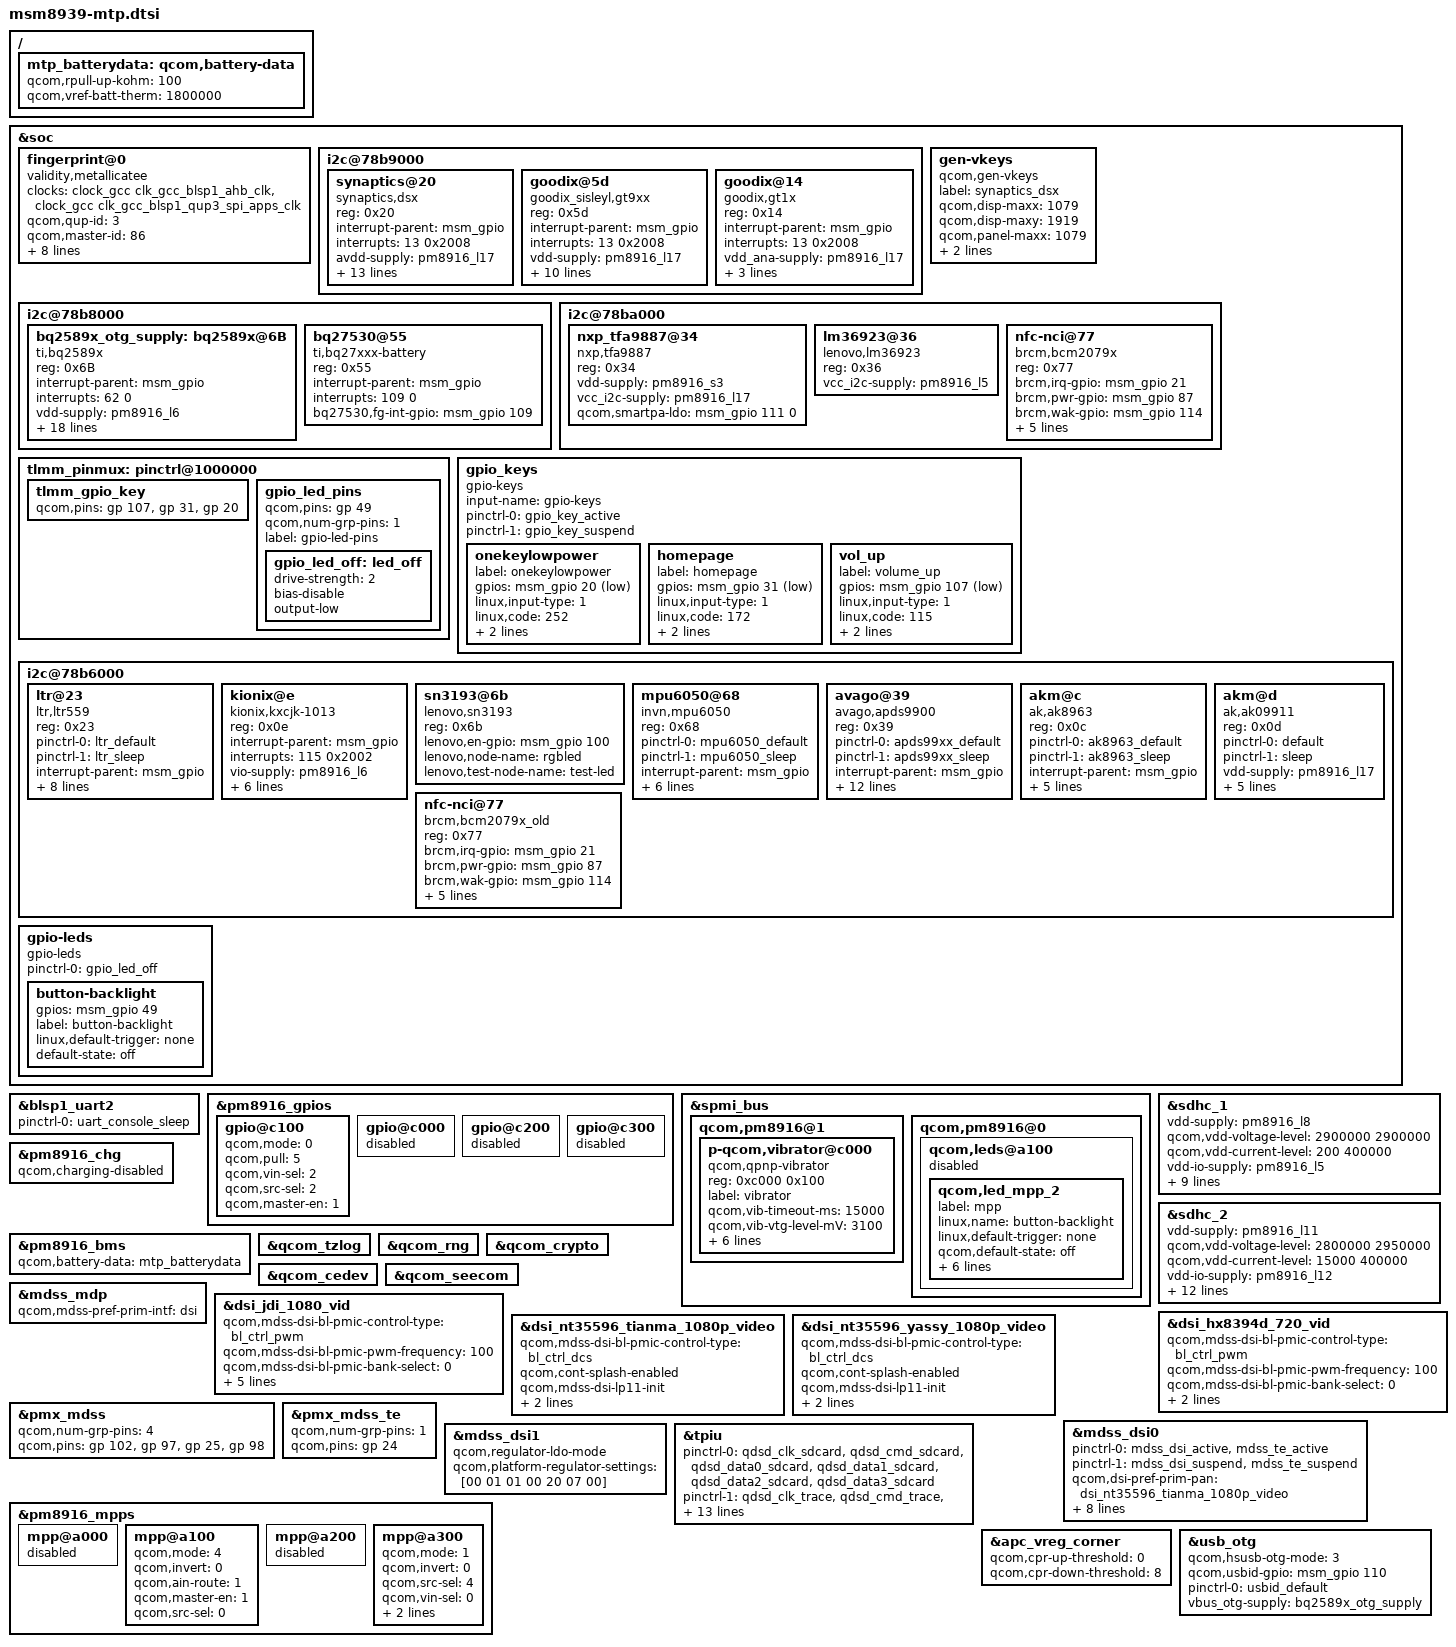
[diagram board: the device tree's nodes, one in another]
/* Copyright (c) 2014-2015, The Linux Foundation. All rights reserved.
 *
 * This program is free software; you can redistribute it and/or modify
 * it under the terms of the GNU General Public License version 2 and
 * only version 2 as published by the Free Software Foundation.
 *
 * This program is distributed in the hope that it will be useful,
 * but WITHOUT ANY WARRANTY; without even the implied warranty of
 * MERCHANTABILITY or FITNESS FOR A PARTICULAR PURPOSE.  See the
 * GNU General Public License for more details.
 */

#include "msm8939-pinctrl.dtsi"
#include "msm8939-camera-sensor-mtp.dtsi"

&soc {
    /* lenovo-sw, chenzz3, lock spi in trustzone, begin */
    fingerprint@0 {
        /* driver name */
        compatible = "validity,metallicatee";
        /* pinctrl for spi */
        /*qcom,use-pinctrl;
        pinctrl-names = "default", "sleep";
        pinctrl-0 = <&spi0_default &spi0_cs0_active>;
        pinctrl-1 = <&spi0_sleep &spi0_cs0_sleep>;*/
        /* clock for spi */
        clocks = <&clock_gcc clk_gcc_blsp1_ahb_clk>,
                 <&clock_gcc clk_gcc_blsp1_qup3_spi_apps_clk>;
        clock-names = "iface_clk", "core_clk";
        /* pass BLSP ID to TZ */
        qcom,qup-id = <3>;
        /* other setting */
        qcom,master-id = <86>;
        /*reg = <0>;
        spi-max-frequency = <11000000>;*/
        /* sensor configuration */
        interrupt-parent = <&msm_gpio>;
        interrupts = <121 0>;
        synaptics,gpio_drdy = <&msm_gpio 121 0x1>;
        synaptics,gpio_sleep = <&msm_gpio 120 0x0>;
        synaptics,gpio_3p3v = <&msm_gpio 82 0x1>;
        vdd-supply = <&pm8916_l16>;
        qcom,vdd-voltage-level = <1800000 1800000>;
        qcom,vdd-current-level = <200 400000>;
    };
    /* lenovo-sw, chenzz3, lock spi in trustzone, end */
	i2c@78b9000 { /* BLSP1 QUP5 */
		synaptics@20 {
			compatible = "synaptics,dsx";
			reg = <0x20>;
			interrupt-parent = <&msm_gpio>;
			interrupts = <13 0x2008>;
			avdd-supply = <&pm8916_l17>;
			vdd-supply = <&pm8916_l6>;
			/* pins used by touchscreen */
			pinctrl-names = "pmx_ts_active","pmx_ts_suspend","pmx_ts_suspend";
			pinctrl-0 = <&ts_int_active &ts_reset_active>;
			pinctrl-1 = <&ts_int_suspend &ts_reset_suspend>;
			pinctrl-2 = <&ts_release>;
			synaptics,irq-gpio = <&msm_gpio 13 0x2008>;
			synaptics,reset-gpio = <&msm_gpio 12 0x0>;
			synaptics,i2c-pull-up;
			synaptics,power-down;
			synaptics,disable-gpios;
			synaptics,display-coords = <0 0 1079 1919>;
			synaptics,panel-coords = <0 0 1079 2084>;
			/* Underlying clocks used by secure touch */
			clocks = <&clock_gcc clk_gcc_blsp1_ahb_clk>,
			 <&clock_gcc clk_gcc_blsp1_qup5_i2c_apps_clk>;
			clock-names = "iface_clk", "core_clk";
		};

        /* Begin, lenovo-sw wengjun1 add 2015-3-1, add for touchpanel config. */
		goodix@5d {
			compatible = "goodix_sisleyl,gt9xx";
			reg = <0x5d>;
			interrupt-parent = <&msm_gpio>;
			interrupts = <13 0x2008>;
			vdd-supply = <&pm8916_l17>;
			vcc_i2c-supply = <&pm8916_l6>;
			/* pins used by touchscreen */
			pinctrl-names = "pmx_ts_active","pmx_ts_suspend";
			pinctrl-0 = <&ts_int_active &ts_reset_active>;
			pinctrl-1 = <&ts_int_suspend &ts_reset_suspend>;
			goodix,reset-gpio = <&msm_gpio 12 0x0>;
			goodix,irq-gpio = <&msm_gpio 13 0x2008>;
			goodix,ctp-gpio = <&msm_gpio 74 0x0>;
			//goodix,ldo-en-gpio = <&msmgpio 15 0x00>;
			goodix,panel-coords = <0 0 1080 1920>;
			goodix,display-coords = <0 0 1080 1920>;
			goodix,button-map= <158 102 139>;
			goodix,family-id = <0x0>;
		};
        /* End, lenovo-sw wengjun1 add 2015-3-1, add for touchpanel config. */

        /* Begin, lenovo-sw wengjun1 add 2015-3-1, add for touchpanel config. */

		goodix@14 {
			compatible = "goodix,gt1x";
			reg = <0x14>;
			interrupt-parent = <&msm_gpio>;
			interrupts = <13 0x2008>;
			vdd_ana-supply = <&pm8916_l17>;
			vcc_i2c-supply = <&pm8916_l6>;
			goodix,rst-gpio = <&msm_gpio 12 0x00>;
			goodix,irq-gpio = <&msm_gpio 13 0x00>;
            };
        /* End, lenovo-sw wengjun1 add 2015-3-1, add for touchpanel config. */
	};

	gen-vkeys {
		compatible = "qcom,gen-vkeys";
		label = "synaptics_dsx";
		qcom,disp-maxx = <1079>;
		qcom,disp-maxy = <1919>;
		qcom,panel-maxx = <1079>;
		qcom,panel-maxy = <2084>;
		qcom,key-codes = <158 139 172 217>;
	};
	
	i2c@78b8000 { /* BLSP1 QUP4 */
	bq2589x_otg_supply: bq2589x@6B {
			compatible = "ti,bq2589x";
			reg = <0x6B>;
			interrupt-parent = <&msm_gpio>;
			interrupts = <62 0>;
			vdd-supply = <&pm8916_l6>;
			/* pins used by touchscreen 
			pinctrl-names = "pmx_ts_active","pmx_ts_suspend";
			pinctrl-0 = <&ts_int_active &ts_reset_active>;
			pinctrl-1 = <&ts_int_suspend &ts_reset_suspend>;*/
			charger,en-gpio = <&msm_gpio 52 0x0>;
			charger,irq-gpio = <&msm_gpio 62 0>;
			charger,ok-gpio = <&msm_gpio 100 0>;
			charger,fast-charger-en-gpio = <&msm_gpio 3 0>;
			//charger,otg-en-gpio = <&msm_gpio 72 0>;
			charger,otg-short-gpio = <&msm_gpio 75 0>;
			charger,max-temp = <500>;
			charger,min-temp = <0>;
			charger,warm-temp = <460>;
			charger,cool-temp = <150>;
			charger,ichg-max = <500>;
			charger,ibat-max = <2000>;
			charger,ibat-warm = <2000>;
			charger,ibat-cool = <480>;
			charger,vbat-warm = <4112>;
			charger,vbat-cool = <4352>;
			charger,vbat-mv = <4352>;
			charger,iterm-ma = <150>;
			regulator-name = "bq2589x_otg_vreg";
		};
		bq27530@55 {
			reg = <0x55>;
	        compatible = "ti,bq27xxx-battery";
			interrupt-parent = <&msm_gpio>;
			interrupts = <109 0>;
			bq27530,fg-int-gpio = <&msm_gpio 109 0>;
           };

	};

	i2c@78ba000 { /* BLSP1 QUP6 */
		//lenovo-sw lumy1 remove for bcm nfc
		/*nfc-nci@e {
			compatible = "qcom,nfc-nci";
			reg = <0x0e>;
			qcom,irq-gpio = <&msm_gpio 21 0x00>;
			qcom,dis-gpio = <&msm_gpio 20 0x00>;
			qcom,clk-src = "BBCLK2";
			interrupt-parent = <&msm_gpio>;
			interrupts = <21 0>;
			interrupt-names = "nfc_irq";
			pinctrl-names = "nfc_active","nfc_suspend";
			pinctrl-0 = <&nfc_int_active &nfc_disable_active>;
			pinctrl-1 = <&nfc_int_suspend &nfc_disable_suspend>;
			qcom,clk-gpio = <&pm8916_gpios 2 0>;
			clocks = <&clock_rpm clk_bb_clk2_pin>;
			clock-names = "ref_clk";
		};*/

	/* lenovo-sw zhangrc2 add for smartpa begin */
    nxp_tfa9887@34 {
		compatible = "nxp,tfa9887";
		reg = <0x34>;
		vdd-supply = <&pm8916_s3>;
		vcc_i2c-supply = <&pm8916_l17>;
        qcom,smartpa-ldo = <&msm_gpio 111 0>;
		};
    /* lenovo-sw zhangrc2 add for smartpa end */

	    /*lenovo.sw2 houdz1 add for lm36923 start*/
		lm36923@36 {
			compatible = "lenovo,lm36923";
			reg = <0x36>;
			vcc_i2c-supply = <&pm8916_l5>;
		};
	    /*lenovo.sw2 houdz1 add for lm36923 end*/
		/* lenovo-sw lumy1 add for brcm2079x nfc*/
		/*nq@2b {
			compatible = "qcom,nq-nci";
			reg = <0x2b>;
			qcom,nq-irq = <&msm_gpio 21 0x00>;
			qcom,nq-ven = <&msm_gpio 20 0x00>;
			qcom,nq-firm = <&msm_gpio 45 0x00>;
			qcom,nq-clkreq = <&pm8916_gpios 2 0>;
			qcom,clk-src = "BBCLK2";
			interrupt-parent = <&msm_gpio>;
			interrupts = <21 0>;
			interrupt-names = "nfc_irq";
			pinctrl-names = "nfc_active","nfc_suspend";
			pinctrl-0 = <&nfc_int_active &nfc_disable_active>;
			pinctrl-1 = <&nfc_int_suspend &nfc_disable_suspend>;
			clocks = <&clock_rpm clk_bb_clk2_pin>;
			clock-names = "ref_clk";
		};*/
		nfc-nci@77 {
		    compatible = "brcm,bcm2079x";
		    reg = <0x77>;
		    brcm,irq-gpio = <&msm_gpio 21 0x00>;
		    brcm,pwr-gpio = <&msm_gpio 87 0x00>;
		    brcm,wak-gpio = <&msm_gpio 114 0x00>;
		    interrupt-parent = <&msm_gpio>;
		    interrupts = <21 0>;
		    vcc_i2c-supply = <&pm8916_l5>;
		    qcom,clk-gpio = <&pm8916_gpios 2 0>;
		    clocks = <&clock_rpm clk_bb_clk2_pin>;
		    clock-names = "ref_clk";
		};
	};
/*add by lixh10 for one key power down && home key 2015-03-10 start*/
	tlmm_pinmux: pinctrl@1000000 {
			tlmm_gpio_key {
			qcom,pins = <&gp 107>, <&gp 31>, <&gp 20>;
			};
		};
	gpio_keys {
		compatible = "gpio-keys";
		input-name = "gpio-keys";
		pinctrl-names = "tlmm_gpio_key_active","tlmm_gpio_key_suspend";
		pinctrl-0 = <&gpio_key_active>;
		pinctrl-1 = <&gpio_key_suspend>;

		onekeylowpower {
			label = "onekeylowpower";
			gpios = <&msm_gpio 20 0x1>;
			linux,input-type = <1>;
			linux,code = <252>;
			gpio-key,wakeup;
			debounce-interval = <15>;
		};

		homepage {
			label = "homepage";
			gpios = <&msm_gpio 31 0x1>;
			linux,input-type = <1>;
			linux,code = <172>;
			gpio-key,wakeup;
			debounce-interval = <15>;
		};

		vol_up {
			label = "volume_up";
			gpios = <&msm_gpio 107 0x1>;
			linux,input-type = <1>;
			linux,code = <115>;
			gpio-key,wakeup;
			debounce-interval = <15>;
		};
	};
/*add by lixh10 for one key power down && home key 2015-03-10 end*/
	i2c@78b6000 { /* BLSP1 QUP2 */
		/*lenovo-sw caoyi1 add for P-sensor and L-sensor  begin*/
		ltr@23 { /*ALS and proximity sensor*/
			compatible = "ltr,ltr559";
			reg = <0x23>;
			pinctrl-names = "default","sleep";
			pinctrl-0 = <&ltr_default>;
			pinctrl-1 = <&ltr_sleep>;
			interrupt-parent = <&msm_gpio>;
			interrupts = <113 0x2002>;
			liteon,intr=<113>;
			ltr,irq-gpio = <&msm_gpio 113 0x2002>;
			vdd-supply = <&pm8916_l17>;
			vio-supply = <&pm8916_l6>;
			ltr,ps-threshold = <150>;
			ltr,ps-hysteresis-threshold = <80>;
			ltr,als-polling-time = <200>;
		};
		/*lenovo-sw caoyi1 add for P-sensor and L-sensor  end*/

		/*lenovo-sw caoyi1 modify for G-sensor 20150508 begin*/
		kionix@e {/*Accelerometer sensor*/
			compatible = "kionix,kxcjk-1013";
			reg = <0x0e>;
			interrupt-parent = <&msm_gpio>;
			interrupts = <115 0x2002>;
			/*vdd-supply = <&pm8916_l17>;*/
			vio-supply = <&pm8916_l6>;
			kionix,min_interval = <5>;
			kionix,poll_interval = <100>;
			kionix,accel_direction = <3>;
			kionix,accel_irq_use_drdy = <0>;
			kionix,accel_res = <12>;	
			kionix,accel_g_range = <2>;
		};
		/*lenovo-sw caoyi1 modify for G-sensor 20150508 end*/

		/*lenovo.sw2 houdz1 add(start)*/
		sn3193@6b {
			compatible = "lenovo,sn3193";
			reg = <0x6b>;
			lenovo,en-gpio = <&msm_gpio 100 0x00>;
			lenovo,node-name = "rgbled";
			lenovo,test-node-name = "test-led";
		};
		/*lenovo.sw2 houdz1 add(end)*/
		mpu6050@68 { /* Gyroscope and accelerometer sensor combo */
			compatible = "invn,mpu6050";
			reg = <0x68>;
			pinctrl-names = "mpu_default","mpu_sleep";
			pinctrl-0 = <&mpu6050_default>;
			pinctrl-1 = <&mpu6050_sleep>;
			interrupt-parent = <&msm_gpio>;
			interrupts = <115 0x2>;
			vdd-supply = <&pm8916_l17>;
			vlogic-supply = <&pm8916_l16>;
			vi2c-supply = <&pm8916_l6>;
			invn,gpio-int = <&msm_gpio 115 0x2>;
			invn,place = "Portrait Down Back Side";
		};

		avago@39 { /* Ambient light and proximity sensor */
			compatible = "avago,apds9900";
			reg = <0x39>;
			pinctrl-names = "default","sleep";
			pinctrl-0 = <&apds99xx_default>;
			pinctrl-1 = <&apds99xx_sleep>;
			interrupt-parent = <&msm_gpio>;
			interrupts = <113 0x2002>;
			vdd-supply = <&pm8916_l17>;
			vio-supply = <&pm8916_l6>;
			avago,irq-gpio = <&msm_gpio 113 0x2002>;
			avago,ps-threshold = <600>;
			avago,ps-hysteresis-threshold = <500>;
			avago,ps-pulse = <8>;
			avago,ps-pgain = <0>;
			avago,als-B = <186>;
			avago,als-C = <75>;
			avago,als-D = <129>;
			avago,ga-value = <560>;
		};

		akm@c {
			compatible = "ak,ak8963";
			reg = <0x0c>;
			pinctrl-names = "ak8963_default", "ak8963_sleep";
			pinctrl-0 = <&ak8963_default>;
			pinctrl-1 = <&ak8963_sleep>;
			interrupt-parent = <&msm_gpio>;
			interrupts = <69 0x2>;
			vdd-supply = <&pm8916_l17>;
			vio-supply = <&pm8916_l6>;
			ak,layout = <0x6>;
			ak,auto-report;
		};

		/*lenovo-sw caoyi1 add for M-sensor begin*/
		akm@d {
			compatible = "ak,ak09911";
			reg = <0x0d>;
			pinctrl-names = "default","sleep";
			pinctrl-0 = <&default>;
			pinctrl-1 = <&sleep>;
			vdd-supply = <&pm8916_l17>;
			vio-supply = <&pm8916_l6>;
			akm,layout = <0x0>;
			akm,gpio_rstn = <&msm_gpio 106 0x0>;
			akm,auto-report;
			akm,use-hrtimer;
		};
		/*lenovo-sw caoyi1 add for M-sensor end*/

		/* brcm2079x nfc configuration for old HW<DVT2-2 */
		nfc-nci@77 {
		    compatible = "brcm,bcm2079x_old";
		    reg = <0x77>;
		    brcm,irq-gpio = <&msm_gpio 21 0x00>;
		    brcm,pwr-gpio = <&msm_gpio 87 0x00>;
		    brcm,wak-gpio = <&msm_gpio 114 0x00>;
		    interrupt-parent = <&msm_gpio>;
		    interrupts = <21 0>;
		    vcc_i2c-supply = <&pm8916_l6>;
		    qcom,clk-gpio = <&pm8916_gpios 2 0>;
		    clocks = <&clock_rpm clk_bb_clk2_pin>;
		    clock-names = "ref_clk";
		};
	};

	gpio-leds {
		compatible = "gpio-leds";
		status = "okay";
		pinctrl-names = "default";
		pinctrl-0 = <&gpio_led_off>;

		button-backlight {
			gpios = <&msm_gpio 49 0>;
			label = "button-backlight";
			linux,default-trigger = "none";
			default-state = "off";
			//retain-state-suspended;
		};
	};
	tlmm_pinmux: pinctrl@1000000{
		gpio_led_pins {
			qcom,pins = <&gp 49>;
			qcom,num-grp-pins = <1>;
			label = "gpio-led-pins";
			gpio_led_off: led_off {
				drive-strength = <2>;
				bias-disable;
				output-low;
			};
		};

	};
	
};

&blsp1_uart2 {
	status = "ok";
	pinctrl-names = "default";
	pinctrl-0 = <&uart_console_sleep>;
};

&pm8916_gpios {
	gpio@c100 { /* GPIO 2 */
		/* NFC_CLK_REQ */
		qcom,mode = <0>; /* QPNP_PIN_MODE_DIG_IN */
		qcom,pull = <5>; /* QPNP_PIN_PULL_NO */
		qcom,vin-sel = <2>; /* QPNP_PIN_VIN2 */
		qcom,src-sel = <2>; /* QPNP_PIN_SEL_FUNC_1 */
		qcom,master-en = <1>;
	};
};
&spmi_bus {
	qcom,pm8916@1 {
		p-qcom,vibrator@c000 {
//*modify by lixh10 for pwm control 2015-0303 start*/
/*
			status = "okay";
			qcom,vib-timeout-ms = <15000>;
			qcom,vib-vtg-level-mV = <2700>;
*/
			status = "okay";
			compatible = "qcom,qpnp-vibrator";
			reg = <0xc000 0x100>;
			label = "vibrator";
			qcom,vib-timeout-ms = <15000>;
			qcom,vib-vtg-level-mV = <3100>;
			qcom,en-gpio = <&msm_gpio 56 0x00>;
			qcom,mode = "dtest1";
			qcom,pwm-channel = <0>;
			qcom,period-us = <50000>; //40
			qcom,duty-us = <40000>;	//30
			qcom,active-low;
//*modify by lixh10 for pwm control 2015-0303 end*/
		};
	};

	qcom,pm8916@0 {
		qcom,leds@a100 {
			status = "disabled";
			qcom,led_mpp_2 {
				label = "mpp";
				linux,name = "button-backlight";
				linux,default-trigger = "none";
				qcom,default-state = "off";
				qcom,max-current = <40>;
				qcom,current-setting = <5>;
				qcom,id = <6>;
				qcom,mode = "manual";
				qcom,source-sel = <1>;
				qcom,mode-ctrl = <0x60>;
			};
		};
	};
};

&sdhc_1 {
	vdd-supply = <&pm8916_l8>;
	qcom,vdd-voltage-level = <2900000 2900000>;
	qcom,vdd-current-level = <200 400000>;

	vdd-io-supply = <&pm8916_l5>;
	qcom,vdd-io-always-on;
	qcom,vdd-io-lpm-sup;
	qcom,vdd-io-voltage-level = <1800000 1800000>;
	qcom,vdd-io-current-level = <200 60000>;

	pinctrl-names = "active", "sleep";
	pinctrl-0 = <&sdc1_clk_on &sdc1_cmd_on &sdc1_data_on>;
	pinctrl-1 = <&sdc1_clk_off &sdc1_cmd_off &sdc1_data_off>;

	qcom,nonremovable;

	status = "ok";
};

&sdhc_2 {
	vdd-supply = <&pm8916_l11>;
	qcom,vdd-voltage-level = <2800000 2950000>;
	qcom,vdd-current-level = <15000 400000>;

	vdd-io-supply = <&pm8916_l12>;
	qcom,vdd-io-voltage-level = <1800000 2950000>;
	qcom,vdd-io-current-level = <200 50000>;

	pinctrl-names = "active", "sleep";
	pinctrl-0 = <&sdc2_clk_on &sdc2_cmd_on &sdc2_data_on &sdc2_cd_on>;
	pinctrl-1 = <&sdc2_clk_off &sdc2_cmd_off &sdc2_data_off &sdc2_cd_off>;

	#address-cells = <0>;
	interrupt-parent = <&sdhc_2>;
	interrupts = <0 1 2>;
	#interrupt-cells = <1>;
	interrupt-map-mask = <0xffffffff>;
	interrupt-map = <0 &intc 0 125 0
			1 &intc 0 221 0
			2 &msm_gpio 38 0>;
	interrupt-names = "hc_irq", "pwr_irq", "status_irq";
	cd-gpios = <&msm_gpio 38 0x1>;

	status = "ok";
};

&pm8916_chg {
	status = "ok";
	qcom,charging-disabled;
};

/ {
	mtp_batterydata: qcom,battery-data {
		qcom,rpull-up-kohm = <100>;
		qcom,vref-batt-therm = <1800000>;

		#include "batterydata-palladium.dtsi"
	};
};

&pm8916_bms {
	status = "ok";
	qcom,battery-data = <&mtp_batterydata>;
};

&qcom_tzlog {
	status = "okay";
};

&qcom_rng {
	status = "okay";
};

&qcom_crypto {
	status = "okay";
};

&qcom_cedev {
	status = "okay";
};

&qcom_seecom {
	status = "okay";
};

#include "dsi-panel-jdi-1080p-video.dtsi"
#include "dsi-panel-hx8394d-720p-video.dtsi"

#include "lenovo-tianma-dsi-panel-nt35596-1080p-video.dtsi"
#include "lenovo-tianma-nt35596-panel-gamma-p1.dtsi"
#include "lenovo-tianma-nt35596-panel-mode-p1.dtsi"

#include "lenovo-yassy-dsi-panel-nt35596-1080p-video.dtsi"
#include "lenovo-yassy-nt35596-panel-gamma-p1.dtsi"
#include "lenovo-yassy-nt35596-panel-mode-p1.dtsi"

&mdss_mdp {
	qcom,mdss-pref-prim-intf = "dsi";
};

&dsi_jdi_1080_vid {
	qcom,mdss-dsi-bl-pmic-control-type = "bl_ctrl_pwm";
	qcom,mdss-dsi-bl-pmic-pwm-frequency = <100>;
	qcom,mdss-dsi-bl-pmic-bank-select = <0>;
	qcom,mdss-dsi-pwm-gpio = <&pm8916_mpps 4 0>;
	qcom,cont-splash-enabled;
	qcom,mdss-dsi-pan-enable-dynamic-fps;
	qcom,mdss-dsi-pan-fps-update = "dfps_immediate_porch_mode";
};

&dsi_hx8394d_720_vid {
        qcom,mdss-dsi-bl-pmic-control-type = "bl_ctrl_pwm";
        qcom,mdss-dsi-bl-pmic-pwm-frequency = <100>;
        qcom,mdss-dsi-bl-pmic-bank-select = <0>;
        qcom,mdss-dsi-pwm-gpio = <&pm8916_mpps 4 0>;
        qcom,cont-splash-enabled;
};


&dsi_nt35596_tianma_1080p_video{
	qcom,mdss-dsi-bl-pmic-control-type = "bl_ctrl_dcs";
	qcom,cont-splash-enabled;
	qcom,mdss-dsi-lp11-init;
	qcom,mdss-dsi-init-delay-us = <5000>;
	lenovo,panel_id = <0>;
};

&dsi_nt35596_yassy_1080p_video{
	qcom,mdss-dsi-bl-pmic-control-type = "bl_ctrl_dcs";
	qcom,cont-splash-enabled;
	qcom,mdss-dsi-lp11-init;
	qcom,mdss-dsi-init-delay-us = <5000>;
	lenovo,panel_id = <1>;
};

&pmx_mdss {
	qcom,num-grp-pins = <4>;
	qcom,pins = <&gp 102>, <&gp 97>, <&gp 25>, <&gp 98>;
};

&pmx_mdss_te {
	qcom,num-grp-pins = <1>;
	qcom,pins = <&gp 24>;
};

&mdss_dsi0 {
	pinctrl-names = "mdss_default", "mdss_sleep";
	pinctrl-0 = <&mdss_dsi_active &mdss_te_active>;
	pinctrl-1 = <&mdss_dsi_suspend &mdss_te_suspend>;
	qcom,dsi-pref-prim-pan = <&dsi_nt35596_tianma_1080p_video>;
	qcom,regulator-ldo-mode;
	qcom,platform-regulator-settings = [00 01 01 00 20 07 00];

	qcom,platform-reset-gpio = <&msm_gpio 25 0>;
	qcom,platform-vsp-gpio = <&msm_gpio 98 0>;
	qcom,platform-vsn-gpio = <&msm_gpio 97 0>;
	qcom,platform-bklight-en-gpio = <&msm_gpio 102 0>;
	qcom,platform-te-gpio = <&msm_gpio 24 0>;
};

&mdss_dsi1 {
	qcom,regulator-ldo-mode;
	qcom,platform-regulator-settings = [00 01 01 00 20 07 00];
};

&pm8916_mpps {
	mpp@a000 { /* MPP 1 */
		/* VDD_PX */
		status = "disabled";
	};

/*lenovo-sw weiweij modified for charger IC ntc*/
	mpp@a100 { /* MPP 2 */
		/* HR LED */
		status = "ok";
		qcom,mode = <4>; /* AIN input */
		qcom,invert = <0>; /* No Invert */
		qcom,ain-route = <1>; /* AMUX 6 */
		qcom,master-en = <1>;
		qcom,src-sel = <0>; /* Function constant */
	};
/*lenovo-sw weiweij modified for charger IC ntc end*/

	mpp@a200 { /* MPP 3 */
		/* VREF DAC */
		status = "disabled";
	};

/*add by lixh10 for isa pwm control 2015-03-10 start*/
	mpp@a300 { /* MPP 4 */
		/* vibrator PWM */
		qcom,mode = <1>;		/* Digital output */
		qcom,invert = <0>;		/* Disable invert */
		qcom,src-sel = <4>;		/* DTEST3 *///lixh10 change 
		qcom,vin-sel = <0>;		/* VPH_PWR */
		qcom,cs-out = <7>;
		qcom,master-en = <1>;		/* Enable MPP */
	};
/*add by lixh10 for isa pwm control 2015-03-10 end*/
};

&pm8916_gpios {
	gpio@c000 { /* GPIO 1 */
		/* Battery UICC Alarm */
		status = "disabled";
	};

	gpio@c100 { /* GPIO 2 */
		/* NFC_CLK_REQ */
		qcom,mode = <0>; /* QPNP_PIN_MODE_DIG_IN */
		qcom,pull = <5>; /* QPNP_PIN_PULL_NO */
		qcom,vin-sel = <2>; /* QPNP_PIN_VIN2 */
		qcom,src-sel = <2>; /* QPNP_PIN_SEL_FUNC_1 */
		qcom,master-en = <1>;
	};

	gpio@c200 { /* GPIO 3 */
		/* External regulator control for WTR */
		status = "disabled";
	};

	gpio@c300 { /* GPIO 4 */
		/* External regulator control for APC */
		status = "disabled";
	};
};

/* CoreSight */
&tpiu {
	pinctrl-names = "sdcard", "trace", "swduart",
			"swdtrc", "jtag", "spmi";
	/* NIDnT */
	pinctrl-0 = <&qdsd_clk_sdcard &qdsd_cmd_sdcard
		     &qdsd_data0_sdcard &qdsd_data1_sdcard
		     &qdsd_data2_sdcard &qdsd_data3_sdcard>;
	pinctrl-1 = <&qdsd_clk_trace &qdsd_cmd_trace
		     &qdsd_data0_trace &qdsd_data1_trace
		     &qdsd_data2_trace &qdsd_data3_trace>;
	pinctrl-2 = <&qdsd_cmd_swduart &qdsd_data0_swduart
		     &qdsd_data1_swduart &qdsd_data2_swduart
		     &qdsd_data3_swduart>;
	pinctrl-3 = <&qdsd_clk_swdtrc &qdsd_cmd_swdtrc
		     &qdsd_data0_swdtrc &qdsd_data1_swdtrc
		     &qdsd_data2_swdtrc &qdsd_data3_swdtrc>;
	pinctrl-4 = <&qdsd_cmd_jtag &qdsd_data0_jtag
		     &qdsd_data1_jtag &qdsd_data2_jtag
		     &qdsd_data3_jtag>;
	pinctrl-5 = <&qdsd_clk_spmi &qdsd_cmd_spmi
		     &qdsd_data0_spmi &qdsd_data3_spmi>;
};

&apc_vreg_corner {
		qcom,cpr-up-threshold = <0>;
		qcom,cpr-down-threshold = <8>;
};

&usb_otg {
	qcom,hsusb-otg-mode = <3>;
	qcom,usbid-gpio = <&msm_gpio 110 0>;
	pinctrl-names = "default";
	pinctrl-0 = <&usbid_default>;
	vbus_otg-supply=<&bq2589x_otg_supply>;
};
